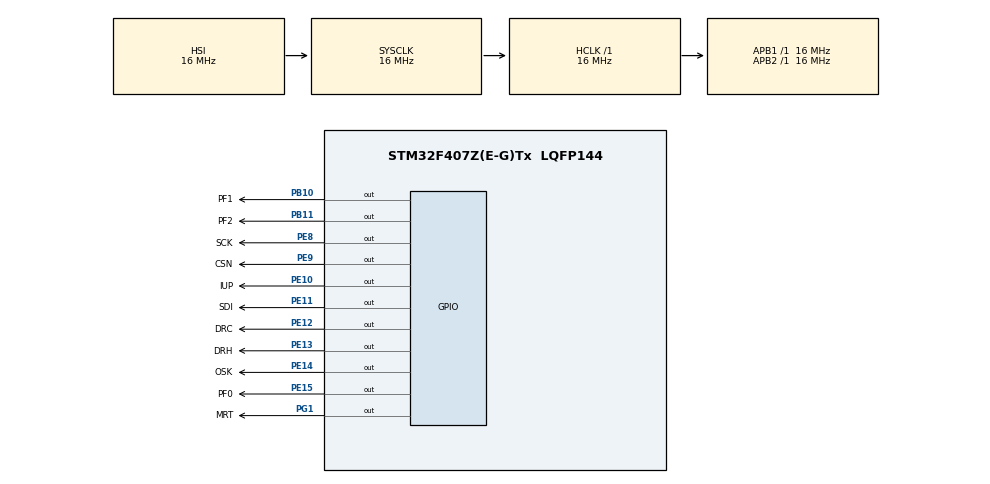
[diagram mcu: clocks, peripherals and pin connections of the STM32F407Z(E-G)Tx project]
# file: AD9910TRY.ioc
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Mcu.Family=STM32F4
Mcu.Name=STM32F407Z(E-G)Tx
Mcu.Package=LQFP144
NVIC.PriorityGroup=NVIC_PRIORITYGROUP_4
PA13.Mode=Serial_Wire
PA13.Signal=SYS_JTMS-SWDIO
PA14.Mode=Serial_Wire
PA14.Signal=SYS_JTCK-SWCLK
PB10.GPIO_Label=PF1
PB10.Signal=GPIO_Output
PB11.GPIO_Label=PF2
PB11.Signal=GPIO_Output
PE10.GPIO_Label=IUP
PE10.Signal=GPIO_Output
PE11.GPIO_Label=SDI
PE11.Signal=GPIO_Output
PE12.GPIO_Label=DRC
PE12.Signal=GPIO_Output
PE13.GPIO_Label=DRH
PE13.Signal=GPIO_Output
PE14.GPIO_Label=OSK
PE14.Signal=GPIO_Output
PE15.GPIO_Label=PF0
PE15.Signal=GPIO_Output
PE8.GPIO_Label=SCK
PE8.Signal=GPIO_Output
PE9.GPIO_Label=CSN
PE9.Signal=GPIO_Output
PG1.GPIO_Label=MRT
PG1.Signal=GPIO_Output
PH0-OSC_IN.Mode=HSE-External-Oscillator
PH0-OSC_IN.Signal=RCC_OSC_IN
PH1-OSC_OUT.Mode=HSE-External-Oscillator
PH1-OSC_OUT.Signal=RCC_OSC_OUT
ProjectManager.HeapSize=0x200
ProjectManager.StackSize=0x400
ProjectManager.TargetToolchain=MDK-ARM V5.32
RCC.AHBFreq_Value=16000000
RCC.APB1Freq_Value=16000000
RCC.APB2Freq_Value=16000000
RCC.CortexFreq_Value=16000000
RCC.HSE_VALUE=25000000
RCC.HSI_VALUE=16000000
RCC.LSE_VALUE=32768
RCC.SYSCLKFreq_VALUE=16000000
RCC.VCOOutputFreq_Value=192000000
board=custom

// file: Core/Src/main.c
/* USER CODE BEGIN Header */
/**
  ******************************************************************************
  * @file           : main.c
  * @brief          : Main program body
  ******************************************************************************
  * @attention
  *
  * Copyright (c) 2024 STMicroelectronics.
  * All rights reserved.
  *
  * This software is licensed under terms that can be found in the LICENSE file
  * in the root directory of this software component.
  * If no LICENSE file comes with this software, it is provided AS-IS.
  *
  ******************************************************************************
  */
/* USER CODE END Header */
#include "main.h"
#include "gpio.h"
#include "AD9910.h"

void SystemClock_Config(void);

int main(void)
{

  /* MCU Configuration--------------------------------------------------------*/

  /* Reset of all peripherals, Initializes the Flash interface and the Systick. */
  HAL_Init();

  /* Configure the system clock */
  SystemClock_Config();

  /* Initialize all configured peripherals */
  MX_GPIO_Init();
  /* USER CODE BEGIN 2 */
	AD9910_Init();

  /* USER CODE END 2 */

  /* Infinite loop */
  while (1)
  {
	//---------------------------------------------------------------------------------------------------------------------------------
	//函数名称:void AD9910_Singal_Profile_Set(uint8_t addr,uint32_t Freq,uint16_t Amp ,uint16_t Pha)
	//函数功能:AD9910单频Profile通道、频率、幅度、相位设置
	//入口参数:		addr							Profile通道的选择								(0--7)					总共有8个Profile
	//						Freq							单频中的频率的设置					 (1Hz--450MHz)
	//						Amp								单频中的幅度设置						 (0x0000--0x3FFF)
	//						Pha								单频中的相位设置							(0--360°)
	//出口参数:无
	//---------------------------------------------------------------------------------------------------------------------------------
		AD9910_Singal_Profile_Init();																	// 单频PROFILE初始化
		AD9910_Singal_Profile_Set(0, 100000000, 37000, 0);

  }
}

void SystemClock_Config(void)
{
  RCC_OscInitTypeDef RCC_OscInitStruct = {0};
  RCC_ClkInitTypeDef RCC_ClkInitStruct = {0};

  /** Configure the main internal regulator output voltage
  */
  __HAL_RCC_PWR_CLK_ENABLE();
  __HAL_PWR_VOLTAGESCALING_CONFIG(PWR_REGULATOR_VOLTAGE_SCALE1);

  /** Initializes the RCC Oscillators according to the specified parameters
  * in the RCC_OscInitTypeDef structure.
  */
  RCC_OscInitStruct.OscillatorType = RCC_OSCILLATORTYPE_HSI;
  RCC_OscInitStruct.HSIState = RCC_HSI_ON;
  RCC_OscInitStruct.HSICalibrationValue = RCC_HSICALIBRATION_DEFAULT;
  RCC_OscInitStruct.PLL.PLLState = RCC_PLL_NONE;
  if (HAL_RCC_OscConfig(&RCC_OscInitStruct) != HAL_OK)
  {
    Error_Handler();
  }

  /** Initializes the CPU, AHB and APB buses clocks
  */
  RCC_ClkInitStruct.ClockType = RCC_CLOCKTYPE_HCLK|RCC_CLOCKTYPE_SYSCLK
                              |RCC_CLOCKTYPE_PCLK1|RCC_CLOCKTYPE_PCLK2;
  RCC_ClkInitStruct.SYSCLKSource = RCC_SYSCLKSOURCE_HSI;
  RCC_ClkInitStruct.AHBCLKDivider = RCC_SYSCLK_DIV1;
  RCC_ClkInitStruct.APB1CLKDivider = RCC_HCLK_DIV1;
  RCC_ClkInitStruct.APB2CLKDivider = RCC_HCLK_DIV1;

  if (HAL_RCC_ClockConfig(&RCC_ClkInitStruct, FLASH_LATENCY_0) != HAL_OK)
  {
    Error_Handler();
  }
}

void Error_Handler(void)
{
  __disable_irq();
  while (1)
  {
  }
}
